VERSION "created by canmatrix"

NS_ :

BS_:

BU_: User ADM_PC_LL25 ADM_PC_BC25 ADM_PC_BP25 ADM_PC_BI25

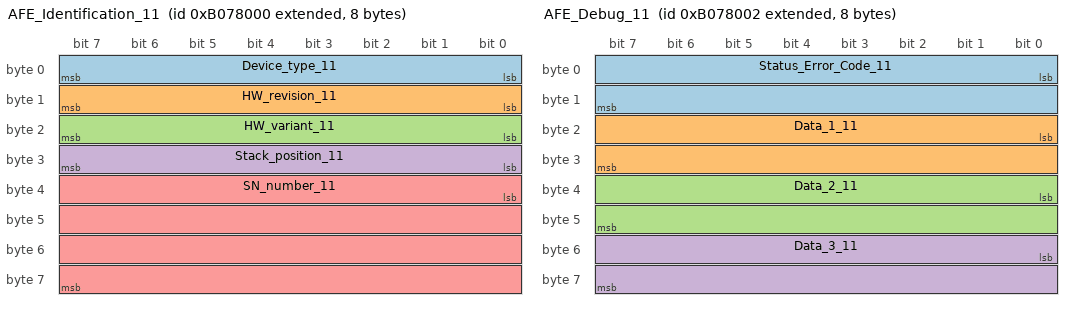
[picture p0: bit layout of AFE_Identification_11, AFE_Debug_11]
BO_ 2332524544 AFE_Identification_11: 8 ADM_PC_BP25
 SG_ Device_type_11 : 0|8@1+ (1,0) [0|255] "" Vector__XXX
 SG_ HW_revision_11 : 8|8@1+ (1,0) [0|255] "" Vector__XXX
 SG_ HW_variant_11 : 16|8@1+ (1,0) [0|255] "" Vector__XXX
 SG_ Stack_position_11 : 24|8@1+ (1,0) [0|255] "" Vector__XXX
 SG_ SN_number_11 : 32|32@1+ (1,0) [0|4294967295] "" Vector__XXX

BO_ 2332524545 AFE_FwInfo_11: 8 ADM_PC_BP25
 SG_ FW_info_mux_11 M : 56|8@1+ (1,0) [0|255] "" Vector__XXX
 SG_ FW_revision_0_11 m0 : 0|8@1+ (1,0) [0|255] "" Vector__XXX
 SG_ FW_revision_1_11 m0 : 8|8@1+ (1,0) [0|255] "" Vector__XXX
 SG_ FW_revision_2_11 m0 : 16|8@1+ (1,0) [0|255] "" Vector__XXX
 SG_ FW_revision_3_11 m0 : 24|8@1+ (1,0) [0|255] "" Vector__XXX
 SG_ FW_revision_4_11 m0 : 32|8@1+ (1,0) [0|255] "" Vector__XXX
 SG_ FW_revision_5_11 m0 : 40|8@1+ (1,0) [0|255] "" Vector__XXX
 SG_ FW_revision_6_11 m0 : 48|8@1+ (1,0) [0|255] "" Vector__XXX
 SG_ FW_revision_7_11 m1 : 0|8@1+ (1,0) [0|255] "" Vector__XXX
 SG_ FW_revision_8_11 m1 : 8|8@1+ (1,0) [0|255] "" Vector__XXX
 SG_ FW_revision_9_11 m1 : 16|8@1+ (1,0) [0|255] "" Vector__XXX
 SG_ FW_revision_10_11 m1 : 24|8@1+ (1,0) [0|255] "" Vector__XXX
 SG_ FW_revision_11_11 m1 : 32|8@1+ (1,0) [0|255] "" Vector__XXX
 SG_ FW_revision_12_11 m1 : 40|8@1+ (1,0) [0|255] "" Vector__XXX
 SG_ FW_revision_13_11 m1 : 48|8@1+ (1,0) [0|255] "" Vector__XXX
 SG_ FW_datecode_0_11 m2 : 0|8@1+ (1,0) [0|255] "" Vector__XXX
 SG_ FW_datecode_1_11 m2 : 8|8@1+ (1,0) [0|255] "" Vector__XXX
 SG_ FW_datecode_2_11 m2 : 16|8@1+ (1,0) [0|255] "" Vector__XXX
 SG_ FW_datecode_3_11 m2 : 24|8@1+ (1,0) [0|255] "" Vector__XXX
 SG_ FW_datecode_4_11 m2 : 32|8@1+ (1,0) [0|255] "" Vector__XXX
 SG_ FW_datecode_5_11 m2 : 40|8@1+ (1,0) [0|255] "" Vector__XXX
 SG_ FW_datecode_6_11 m2 : 48|8@1+ (1,0) [0|255] "" Vector__XXX
 SG_ FW_datecode_7_11 m3 : 0|8@1+ (1,0) [0|255] "" Vector__XXX
 SG_ FW_datecode_8_11 m3 : 8|8@1+ (1,0) [0|255] "" Vector__XXX
 SG_ FW_datecode_9_11 m3 : 16|8@1+ (1,0) [0|255] "" Vector__XXX
 SG_ FW_datecode_10_11 m3 : 24|8@1+ (1,0) [0|255] "" Vector__XXX
 SG_ FW_datecode_11_11 m3 : 32|8@1+ (1,0) [0|255] "" Vector__XXX
 SG_ FW_datecode_12_11 m3 : 40|8@1+ (1,0) [0|255] "" Vector__XXX
 SG_ FW_datecode_13_11 m3 : 48|8@1+ (1,0) [0|255] "" Vector__XXX

BO_ 2332524557 _AFE_Boot_FwInfo_11: 8 ADM_PC_BP25
 SG_ Boot_FW_info_mux_11 M : 56|8@1+ (1,0) [0|255] "" Vector__XXX
 SG_ FW_revision_0_11 m0 : 0|8@1+ (1,0) [0|255] "" Vector__XXX
 SG_ FW_revision_1_11 m0 : 8|8@1+ (1,0) [0|255] "" Vector__XXX
 SG_ FW_revision_2_11 m0 : 16|8@1+ (1,0) [0|255] "" Vector__XXX
 SG_ FW_revision_3_11 m0 : 24|8@1+ (1,0) [0|255] "" Vector__XXX
 SG_ FW_revision_4_11 m0 : 32|8@1+ (1,0) [0|255] "" Vector__XXX
 SG_ FW_revision_5_11 m0 : 40|8@1+ (1,0) [0|255] "" Vector__XXX
 SG_ FW_revision_6_11 m0 : 48|8@1+ (1,0) [0|255] "" Vector__XXX
 SG_ FW_revision_7_11 m1 : 0|8@1+ (1,0) [0|255] "" Vector__XXX
 SG_ FW_revision_8_11 m1 : 8|8@1+ (1,0) [0|255] "" Vector__XXX
 SG_ FW_revision_9_11 m1 : 16|8@1+ (1,0) [0|255] "" Vector__XXX
 SG_ FW_revision_10_11 m1 : 24|8@1+ (1,0) [0|255] "" Vector__XXX
 SG_ FW_revision_11_11 m1 : 32|8@1+ (1,0) [0|255] "" Vector__XXX
 SG_ FW_revision_12_11 m1 : 40|8@1+ (1,0) [0|255] "" Vector__XXX
 SG_ FW_revision_13_11 m1 : 48|8@1+ (1,0) [0|255] "" Vector__XXX
 SG_ FW_datecode_0_11 m2 : 0|8@1+ (1,0) [0|255] "" Vector__XXX
 SG_ FW_datecode_1_11 m2 : 8|8@1+ (1,0) [0|255] "" Vector__XXX
 SG_ FW_datecode_2_11 m2 : 16|8@1+ (1,0) [0|255] "" Vector__XXX
 SG_ FW_datecode_3_11 m2 : 24|8@1+ (1,0) [0|255] "" Vector__XXX
 SG_ FW_datecode_4_11 m2 : 32|8@1+ (1,0) [0|255] "" Vector__XXX
 SG_ FW_datecode_5_11 m2 : 40|8@1+ (1,0) [0|255] "" Vector__XXX
 SG_ FW_datecode_6_11 m2 : 48|8@1+ (1,0) [0|255] "" Vector__XXX
 SG_ FW_datecode_7_11 m3 : 0|8@1+ (1,0) [0|255] "" Vector__XXX
 SG_ FW_datecode_8_11 m3 : 8|8@1+ (1,0) [0|255] "" Vector__XXX
 SG_ FW_datecode_9_11 m3 : 16|8@1+ (1,0) [0|255] "" Vector__XXX
 SG_ FW_datecode_10_11 m3 : 24|8@1+ (1,0) [0|255] "" Vector__XXX
 SG_ FW_datecode_11_11 m3 : 32|8@1+ (1,0) [0|255] "" Vector__XXX
 SG_ FW_datecode_12_11 m3 : 40|8@1+ (1,0) [0|255] "" Vector__XXX
 SG_ FW_datecode_13_11 m3 : 48|8@1+ (1,0) [0|255] "" Vector__XXX

BO_ 2332524546 AFE_Debug_11: 8 ADM_PC_BP25
 SG_ Status_Error_Code_11 : 0|16@1+ (1,0) [0|65535] "" Vector__XXX
 SG_ Data_1_11 : 16|16@1+ (1,0) [0|65535] "" Vector__XXX
 SG_ Data_2_11 : 32|16@1+ (1,0) [0|65535] "" Vector__XXX
 SG_ Data_3_11 : 48|16@1+ (1,0) [0|65535] "" Vector__XXX

BO_ 2332524551 AFE_Status_11: 8 ADM_PC_BP25
 SG_ Running_11 : 0|1@1+ (1,0) [0|1] "" Vector__XXX
 SG_ PWM_11 : 1|1@1+ (1,0) [0|1] "" Vector__XXX
 SG_ Current_dc_loop_mode_11 : 2|1@1+ (1,0) [0|1] "" Vector__XXX
 SG_ Current_ac_loop_mode_11 : 3|1@1+ (1,0) [0|1] "" Vector__XXX
 SG_ Buck_11 : 5|1@1+ (1,0) [0|1] "" Vector__XXX
 SG_ Boost_11 : 6|1@1+ (1,0) [0|1] "" Vector__XXX
 SG_ Precharge_dc_buck_mode_11 : 7|1@1+ (1,0) [0|1] "" Vector__XXX
 SG_ Precharge_dc_boost_mode_11 : 8|1@1+ (1,0) [0|1] "" Vector__XXX
 SG_ Rectifier_3ph_11 : 9|1@1+ (1,0) [0|1] "" Vector__XXX
 SG_ Stack_mode_11 : 10|1@1+ (1,0) [0|1] "" Vector__XXX
 SG_ Master_11 : 11|1@1+ (1,0) [0|1] "" Vector__XXX
 SG_ Slave_11 : 12|1@1+ (1,0) [0|1] "" Vector__XXX
 SG_ Inverter_1ph_11 : 13|1@1+ (1,0) [0|1] "" Vector__XXX
 SG_ Boost_Neutral_11 : 14|1@1+ (1,0) [0|1] "" Vector__XXX
 SG_ Rectifier_1ph_11 : 15|1@1+ (1,0) [0|1] "" Vector__XXX
 SG_ Inverter_3ph_11 : 16|1@1+ (1,0) [0|1] "" Vector__XXX
 SG_ Ready_11 : 17|1@1+ (1,0) [0|1] "" Vector__XXX
 SG_ Inverter_1ph_Sync_11 : 18|1@1+ (1,0) [0|1] "" Vector__XXX
 SG_ Neutral_11 : 19|1@1+ (1,0) [0|1] "" Vector__XXX
 SG_ Rectifier_1ph_Buck_11 : 20|1@1+ (1,0) [0|1] "" Vector__XXX
 SG_ Inverter_1ph_Boost_11 : 21|1@1+ (1,0) [0|1] "" Vector__XXX
 SG_ Rectifier_distributed_11 : 22|1@1+ (1,0) [0|1] "" Vector__XXX
 SG_ MPPT_buck_11 : 23|1@1+ (1,0) [0|1] "" Vector__XXX
 SG_ MPPT_boost_11 : 24|1@1+ (1,0) [0|1] "" Vector__XXX
 SG_ Buck_2p_float_11 : 25|1@1+ (1,0) [0|1] "" Vector__XXX
 SG_ Inverter_1ph_Distributed_11 : 26|1@1+ (1,0) [0|1] "" Vector__XXX

BO_ 2332524550 AFE_Faults_11: 3 ADM_PC_BP25
 SG_ Protection_trip_internal_11 : 0|1@1+ (1,0) [0|1] "" Vector__XXX
 SG_ Protection_trip_external_11 : 1|1@1+ (1,0) [0|1] "" Vector__XXX
 SG_ Phase_U_overcurrent_11 : 2|1@1+ (1,0) [0|1] "" Vector__XXX
 SG_ Phase_U_overvoltage_11 : 3|1@1+ (1,0) [0|1] "" Vector__XXX
 SG_ Phase_U_undervoltage_11 : 4|1@1+ (1,0) [0|1] "" Vector__XXX
 SG_ Phase_V_overvoltage_11 : 5|1@1+ (1,0) [0|1] "" Vector__XXX
 SG_ Phase_V_undervoltage_11 : 6|1@1+ (1,0) [0|1] "" Vector__XXX
 SG_ Phase_V_overcurrent_11 : 7|1@1+ (1,0) [0|1] "" Vector__XXX
 SG_ Phase_W_overvoltage_11 : 8|1@1+ (1,0) [0|1] "" Vector__XXX
 SG_ Phase_W_undervoltage_11 : 9|1@1+ (1,0) [0|1] "" Vector__XXX
 SG_ Phase_W_overcurrent_11 : 10|1@1+ (1,0) [0|1] "" Vector__XXX
 SG_ DC_undervoltage_11 : 11|1@1+ (1,0) [0|1] "" Vector__XXX
 SG_ DC_overvoltage_11 : 12|1@1+ (1,0) [0|1] "" Vector__XXX
 SG_ MOSFET_overtemperature_11 : 13|1@1+ (1,0) [0|1] "" Vector__XXX
 SG_ Inductor_overtemperature_11 : 14|1@1+ (1,0) [0|1] "" Vector__XXX
 SG_ Keep_Alive_not_served_11 : 15|1@1+ (1,0) [0|1] "" Vector__XXX
 SG_ PLL_not_locked_11 : 16|1@1+ (1,0) [0|1] "" Vector__XXX
 SG_ NFO_11 : 20|1@1+ (1,0) [0|1] "" Vector__XXX
 SG_ Measurement_system_failure_11 : 21|1@1+ (1,0) [0|1] "" Vector__XXX
 SG_ EEPROM_failure_11 : 22|1@1+ (1,0) [0|1] "" Vector__XXX
 SG_ System_11 : 23|1@1+ (1,0) [0|1] "" Vector__XXX

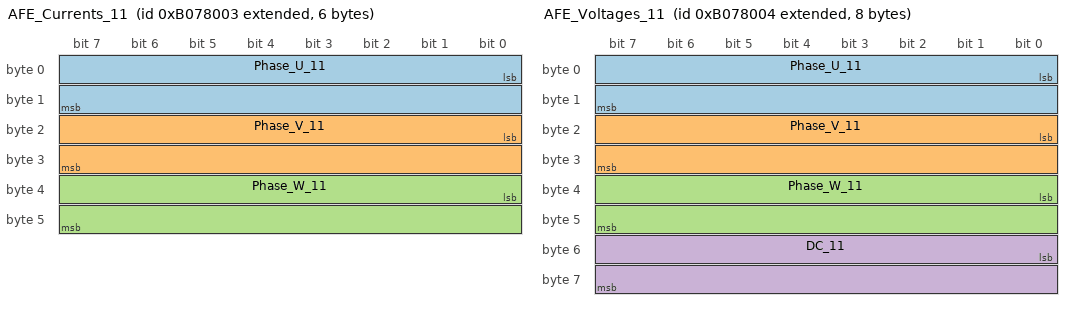
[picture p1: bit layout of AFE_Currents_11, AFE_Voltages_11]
BO_ 2332524547 AFE_Currents_11: 6 ADM_PC_BP25
 SG_ Phase_U_11 : 0|16@1- (0.01,0) [-327.68|327.67] "A" Vector__XXX
 SG_ Phase_V_11 : 16|16@1- (0.01,0) [-327.68|327.67] "A" Vector__XXX
 SG_ Phase_W_11 : 32|16@1- (0.01,0) [-327.68|327.67] "A" Vector__XXX

BO_ 2332524560 AFE_DC_Bus_current_11: 2 ADM_PC_BP25
 SG_ Bus_current_11 : 0|16@1- (0.01,0) [-327.68|327.67] "A" Vector__XXX

BO_ 2332524558 _AFE_Broadcast_11: 8 ADM_PC_BP25
 SG_ Diagnostics_Index_11 M : 56|8@1+ (1,0) [0|255] "" Vector__XXX
 SG_ Phase_U_11 m1 : 8|16@1- (0.01,0) [-327.68|327.67] "A" ADM_PC_BP25
 SG_ Phase_V_11 m1 : 24|16@1- (0.01,0) [-327.68|327.67] "A" ADM_PC_BP25
 SG_ Phase_W_11 m1 : 40|16@1- (0.01,0) [-327.68|327.67] "A" ADM_PC_BP25
 SG_ Stack_position_11 : 0|5@1+ (1,0) [0|31] "" ADM_PC_BP25
 SG_ Group_ID_11 : 5|3@1+ (1,0) [0|7] "" ADM_PC_BP25

BO_ 2332524548 AFE_Voltages_11: 8 ADM_PC_BP25
 SG_ Phase_U_11 : 0|16@1- (0.1,0) [-3276.8|3276.7] "V" Vector__XXX
 SG_ Phase_V_11 : 16|16@1- (0.1,0) [-3276.8|3276.7] "V" Vector__XXX
 SG_ Phase_W_11 : 32|16@1- (0.1,0) [-3276.8|3276.7] "V" Vector__XXX
 SG_ DC_11 : 48|16@1- (0.1,0) [-3276.8|3276.7] "V" Vector__XXX

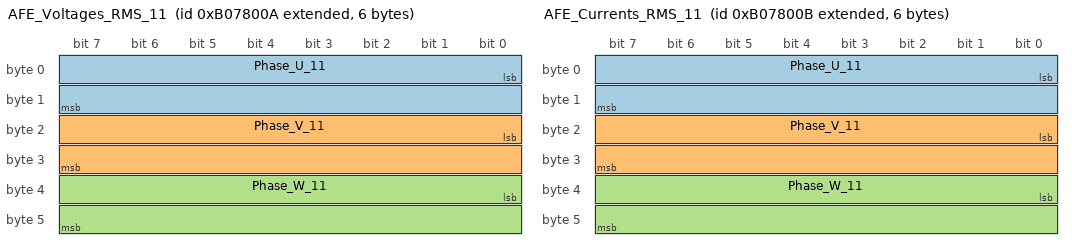
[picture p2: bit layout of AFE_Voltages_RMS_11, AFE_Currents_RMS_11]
BO_ 2332524554 AFE_Voltages_RMS_11: 6 ADM_PC_BP25
 SG_ Phase_U_11 : 0|16@1+ (0.1,0) [0|6553.5] "V" Vector__XXX
 SG_ Phase_V_11 : 16|16@1+ (0.1,0) [0|6553.5] "V" Vector__XXX
 SG_ Phase_W_11 : 32|16@1+ (0.1,0) [0|6553.5] "V" Vector__XXX

BO_ 2332524555 AFE_Currents_RMS_11: 6 ADM_PC_BP25
 SG_ Phase_U_11 : 0|16@1+ (0.01,0) [0.00|655.35] "A" Vector__XXX
 SG_ Phase_V_11 : 16|16@1+ (0.01,0) [0.00|655.35] "A" Vector__XXX
 SG_ Phase_W_11 : 32|16@1+ (0.01,0) [0.00|655.35] "A" Vector__XXX

BO_ 2332524556 AFE_Mains_11: 4 ADM_PC_BP25
 SG_ Frequency_11 : 0|16@1+ (0.01,0) [0.00|655.35] "Hz" Vector__XXX
 SG_ Phase_11 : 16|16@1- (0.1,0) [-3276.8|3276.7] "Deg." Vector__XXX

BO_ 2332524549 AFE_Temperatures_11: 4 ADM_PC_BP25
 SG_ Temp_Bridge_11 : 0|16@1- (0.01,0) [-327.68|327.67] "°C" Vector__XXX
 SG_ Temp_Inductors_11 : 16|16@1- (0.01,0) [-327.68|327.67] "°C" Vector__XXX

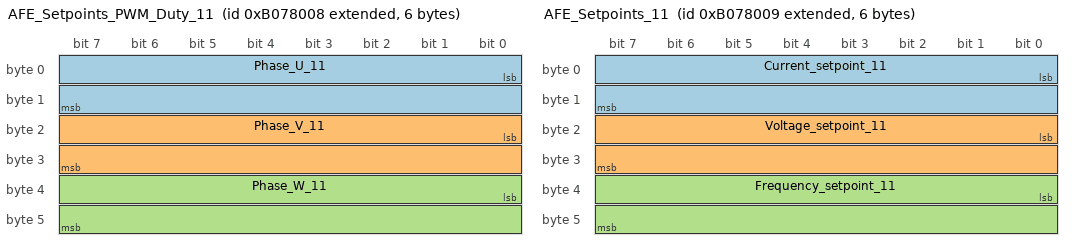
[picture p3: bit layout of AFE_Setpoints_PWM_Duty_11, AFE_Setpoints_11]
BO_ 2332524552 AFE_Setpoints_PWM_Duty_11: 6 ADM_PC_BP25
 SG_ Phase_U_11 : 0|16@1+ (0.001525902,0) [0E-009|99.999987570] "%" Vector__XXX
 SG_ Phase_V_11 : 16|16@1+ (0.001525902,0) [0E-009|99.999987570] "%" Vector__XXX
 SG_ Phase_W_11 : 32|16@1+ (0.001525902,0) [0E-009|99.999987570] "%" Vector__XXX

BO_ 2332524553 AFE_Setpoints_11: 6 ADM_PC_BP25
 SG_ Current_setpoint_11 : 0|16@1- (0.01,0) [-327.68|327.67] "A" Vector__XXX
 SG_ Voltage_setpoint_11 : 16|16@1+ (0.1,0) [0|6553.5] "V" Vector__XXX
 SG_ Frequency_setpoint_11 : 32|16@1+ (0.01,0) [0.00|655.35] "Hz" Vector__XXX

BO_ 2332491872 AFE_Keep_Alive_11: 1 User
 SG_ Keep_Alive_Enable_11 : 0|1@1+ (1,0) [0|1] "" ADM_PC_BP25

BO_ 2332491840 AFE_Mode_Control_11: 8 User
 SG_ Converter_ON_11 : 0|1@1+ (1,0) [0|1] "" ADM_PC_BP25
 SG_ PWM_ON_11 : 1|1@1+ (1,0) [0|1] "" ADM_PC_BP25
 SG_ DC_Current_feedback_ON_11 : 2|1@1+ (1,0) [0|1] "" ADM_PC_BP25
 SG_ AC_Current_feedback_ON_11 : 3|1@1+ (1,0) [0|1] "" ADM_PC_BP25
 SG_ Buck_ON_11 : 5|1@1+ (1,0) [0|1] "" ADM_PC_BP25
 SG_ Boost_ON_11 : 6|1@1+ (1,0) [0|1] "" ADM_PC_BP25
 SG_ Rectifier_3ph_ON_11 : 9|1@1+ (1,0) [0|1] "" ADM_PC_BP25
 SG_ Inverter_1ph_ON_11 : 10|1@1+ (1,0) [0|1] "" ADM_PC_BP25
 SG_ Rectifier_1ph_ON_11 : 11|1@1+ (1,0) [0|1] "" ADM_PC_BP25
 SG_ Boost_Neutral_ON_11 : 12|1@1+ (1,0) [0|1] "" ADM_PC_BP25
 SG_ Inverter_3ph_ON_11 : 13|1@1+ (1,0) [0|1] "" ADM_PC_BP25
 SG_ Inverter_1ph_Sync_ON_11 : 14|1@1+ (1,0) [0|1] "" ADM_PC_BP25
 SG_ Neutral_ON_11 : 15|1@1+ (1,0) [0|1] "" ADM_PC_BP25
 SG_ Rectifier_1ph_Buck_ON_11 : 16|1@1+ (1,0) [0|1] "" ADM_PC_BP25
 SG_ Inverter_1ph_Boost_ON_11 : 17|1@1+ (1,0) [0|1] "" ADM_PC_BP25
 SG_ Rectifier_Distributed_ON_11 : 18|1@1+ (1,0) [0|1] "" ADM_PC_BP25
 SG_ MPPT_buck_ON_11 : 19|1@1+ (1,0) [0|1] "" ADM_PC_BP25
 SG_ MPPT_boost_ON_11 : 20|1@1+ (1,0) [0|1] "" ADM_PC_BP25
 SG_ Buck_2p_float_ON_11 : 21|1@1+ (1,0) [0|1] "" ADM_PC_BP25
 SG_ Inverter_1ph_Distributed_ON_11 : 22|1@1+ (1,0) [0|1] "" ADM_PC_BP25

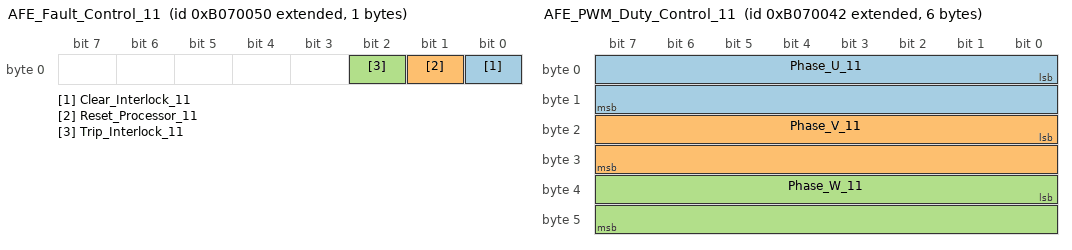
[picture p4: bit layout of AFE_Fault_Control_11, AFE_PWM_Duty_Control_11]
BO_ 2332491856 AFE_Fault_Control_11: 1 User
 SG_ Clear_Interlock_11 : 0|1@1+ (1,0) [0|1] "" ADM_PC_BP25
 SG_ Reset_Processor_11 : 1|1@1+ (1,0) [0|1] "" ADM_PC_BP25
 SG_ Trip_Interlock_11 : 2|1@1+ (1,0) [0|1] "" ADM_PC_BP25

BO_ 2332491841 AFE_Reactive_Current_Setpoint_Co: 2 User
 SG_ Reactive_current_setpoint_11 : 0|16@1- (0.01,0) [-150|150] "A" ADM_PC_BP25

BO_ 2332491842 AFE_PWM_Duty_Control_11: 6 User
 SG_ Phase_U_11 : 0|16@1+ (0.001525902,0) [0E-009|99.999987570] "%" ADM_PC_BP25
 SG_ Phase_V_11 : 16|16@1+ (0.001525902,0) [0E-009|99.999987570] "%" ADM_PC_BP25
 SG_ Phase_W_11 : 32|16@1+ (0.001525902,0) [0E-009|99.999987570] "%" ADM_PC_BP25

BO_ 2332491843 AFE_Current_Setpoint_Control_11: 2 User
 SG_ Current_setpoint_11 : 0|16@1- (0.01,0) [-150|150] "A" ADM_PC_BP25

BO_ 2332491844 AFE_Voltage_Setpoint_Control_11: 2 User
 SG_ Voltage_setpoint_11 : 0|16@1+ (0.1,0) [0|1500] "V" ADM_PC_BP25

BO_ 2332491848 AFE_Frequency_Setpoint_Control_1: 2 User
 SG_ Frequency_setpoint_11 : 0|16@1+ (0.01,0) [40|70] "Hz" ADM_PC_BP25

BO_ 2332491849 AFE_Phase_Setpoint_Control_11: 2 User
 SG_ Phase_setpoint_11 : 0|16@1+ (1,0) [0|360] "deg" ADM_PC_BP25

BO_ 2332491888 AFE_Rectifier_Setpoint_Control_1: 8 User
 SG_ Voltage_setpoint_2_11 : 0|16@1+ (0.1,0) [0|1500] "V" ADM_PC_BP25
 SG_ Current_setpoint_2_11 : 16|16@1- (0.01,0) [-150|150] "A" ADM_PC_BP25

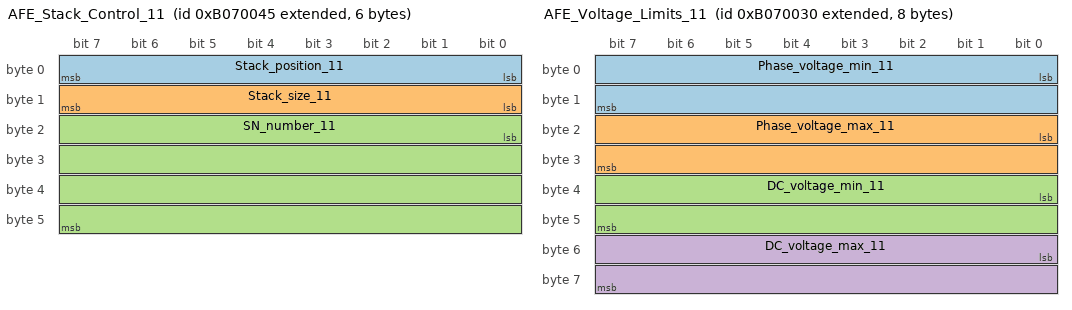
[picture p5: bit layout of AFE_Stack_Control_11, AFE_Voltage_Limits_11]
BO_ 2332491845 AFE_Stack_Control_11: 6 User
 SG_ Stack_position_11 : 0|8@1+ (1,0) [0|255] "" ADM_PC_BP25
 SG_ Stack_size_11 : 8|8@1+ (1,0) [0|255] "" ADM_PC_BP25
 SG_ SN_number_11 : 16|32@1+ (1,0) [0|4294967295] "" ADM_PC_BP25

BO_ 2332491824 AFE_Voltage_Limits_11: 8 User
 SG_ Phase_voltage_min_11 : 0|16@1- (0.1,0) [0|3276.7] "V" ADM_PC_BP25
 SG_ Phase_voltage_max_11 : 16|16@1- (0.1,0) [-3276.8|850] "V" ADM_PC_BP25
 SG_ DC_voltage_min_11 : 32|16@1- (0.1,0) [0|3276.7] "V" ADM_PC_BP25
 SG_ DC_voltage_max_11 : 48|16@1- (0.1,0) [-3276.8|850] "V" ADM_PC_BP25

BO_ 2332491825 AFE_Current_Limits_11: 4 User
 SG_ Phase_current_min_11 : 0|16@1- (0.01,0) [-60|60] "A" ADM_PC_BP25
 SG_ Phase_current_max_11 : 16|16@1- (0.01,0) [-60|60] "A" ADM_PC_BP25

BO_ 2332491852 AFE_Group_Control_11: 1 User
 SG_ Group_ID_11 : 0|8@1+ (1,0) [0|255] "" ADM_PC_BP25

BO_ 2332524559 AFE_Group_Info_11: 1 ADM_PC_BP25
 SG_ Group_ID_11 : 0|8@1+ (1,0) [0|255] "" Vector__XXX

BO_ 2332491873 AFE_System_Flags_Control_11: 8 User
 SG_ Factory_mode_11 : 0|1@1+ (1,0) [0|1] "" ADM_PC_BP25
 SG_ Silent_CAN_mode_11 : 1|1@1+ (1,0) [0|1] "" ADM_PC_BP25

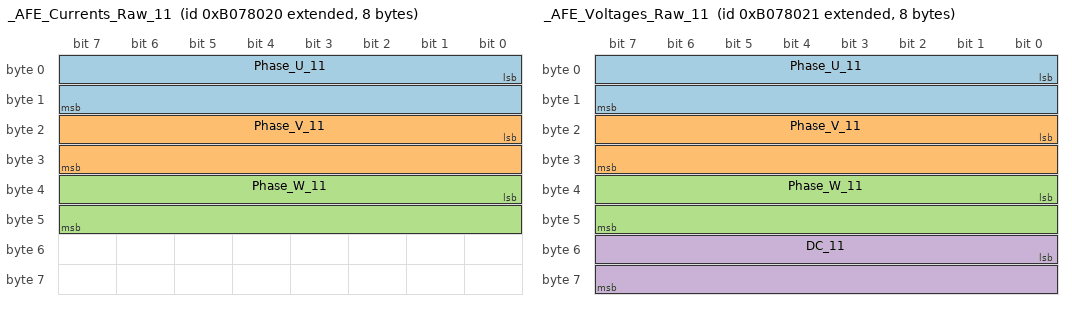
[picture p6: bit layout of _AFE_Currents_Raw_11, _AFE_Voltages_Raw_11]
BO_ 2332524576 _AFE_Currents_Raw_11: 8 ADM_PC_BP25
 SG_ Phase_U_11 : 0|16@1- (1,0) [-32768|32767] "" Vector__XXX
 SG_ Phase_V_11 : 16|16@1- (1,0) [-32768|32767] "" Vector__XXX
 SG_ Phase_W_11 : 32|16@1- (1,0) [-32768|32767] "" Vector__XXX

BO_ 2332524577 _AFE_Voltages_Raw_11: 8 ADM_PC_BP25
 SG_ Phase_U_11 : 0|16@1- (1,0) [-32768|32767] "" Vector__XXX
 SG_ Phase_V_11 : 16|16@1- (1,0) [-32768|32767] "" Vector__XXX
 SG_ Phase_W_11 : 32|16@1- (1,0) [-32768|32767] "" Vector__XXX
 SG_ DC_11 : 48|16@1- (1,0) [-32768|32767] "" Vector__XXX

BO_ 2332491850 _AFE_ADC_Calibration_Mode_11: 1 User
 SG_ Calibration_Index_11 M : 2|5@1+ (1,0) [0|31] "" Vector__XXX
 SG_ Current_U_11 m1 : 0|2@1+ (1,0) [0|3] "" ADM_PC_BP25
 SG_ Current_V_11 m2 : 0|2@1+ (1,0) [0|3] "" ADM_PC_BP25
 SG_ Current_W_11 m3 : 0|2@1+ (1,0) [0|3] "" ADM_PC_BP25
 SG_ Voltage_U_11 m4 : 0|2@1+ (1,0) [0|3] "" ADM_PC_BP25
 SG_ Voltage_V_11 m5 : 0|2@1+ (1,0) [0|3] "" ADM_PC_BP25
 SG_ Voltage_W_11 m6 : 0|2@1+ (1,0) [0|3] "" ADM_PC_BP25
 SG_ Voltage_DC_11 m7 : 0|2@1+ (1,0) [0|3] "" ADM_PC_BP25
 SG_ start_11 : 7|1@1+ (1,0) [0|1] "" ADM_PC_BP25

BO_ 2332491851 _AFE_ADC_Calibration_Setpoint_11: 3 User
 SG_ Calibration_Index_11 M : 16|5@1+ (1,0) [0|31] "" Vector__XXX
 SG_ Current_U_11 m1 : 0|16@1- (0.01,0) [-100|100] "A" ADM_PC_BP25
 SG_ Current_V_11 m2 : 0|16@1- (0.01,0) [-100|100] "A" ADM_PC_BP25
 SG_ Current_W_11 m3 : 0|16@1- (0.01,0) [-100|100] "A" ADM_PC_BP25
 SG_ Voltage_U_11 m4 : 0|16@1+ (0.1,0) [0|1500] "V" ADM_PC_BP25
 SG_ Voltage_V_11 m5 : 0|16@1+ (0.1,0) [0|1500] "V" ADM_PC_BP25
 SG_ Voltage_W_11 m6 : 0|16@1+ (0.1,0) [0|1500] "V" ADM_PC_BP25
 SG_ Voltage_DC_11 m7 : 0|16@1+ (0.1,0) [0|1500] "V" ADM_PC_BP25
 SG_ point_11 : 21|3@1+ (1,0) [0|7] "" ADM_PC_BP25

BO_ 2332491846 _AFE_Calibration_Offset_Update_1: 6 User
 SG_ Calibration_Index_11 M : 16|16@1+ (1,0) [0|65535] "" Vector__XXX
 SG_ Current_U_11 m0 : 0|16@1- (1,0) [-32768|32767] "ADC Counts" ADM_PC_BP25
 SG_ Current_V_11 m1 : 0|16@1- (1,0) [-32768|32767] "ADC Counts" ADM_PC_BP25
 SG_ Current_W_11 m2 : 0|16@1- (1,0) [-32768|32767] "ADC Counts" ADM_PC_BP25
 SG_ Voltage_U_11 m3 : 0|16@1- (1,0) [-32768|32767] "ADC Counts" ADM_PC_BP25
 SG_ Voltage_V_11 m4 : 0|16@1- (1,0) [-32768|32767] "ADC Counts" ADM_PC_BP25
 SG_ Voltage_W_11 m5 : 0|16@1- (1,0) [-32768|32767] "ADC Counts" ADM_PC_BP25
 SG_ Voltage_DC_11 m6 : 0|16@1- (1,0) [-32768|32767] "ADC Counts" ADM_PC_BP25
 SG_ CRC_11 : 32|16@1+ (1,0) [0|65535] "-" ADM_PC_BP25

BO_ 2332491847 _AFE_Calibration_Scale_Update_11: 6 User
 SG_ Calibration_Index_11 M : 16|16@1+ (1,0) [0|65535] "" Vector__XXX
 SG_ Current_U_11 m0 : 0|16@1- (0.0000152587890625,0) [-0.5000000000000000|0.4999847412109375] "scale = 1.0 + value" ADM_PC_BP25
 SG_ Current_V_11 m1 : 0|16@1- (0.0000152587890625,0) [-0.5000000000000000|0.4999847412109375] "scale = 1.0 + value" ADM_PC_BP25
 SG_ Current_W_11 m2 : 0|16@1- (0.0000152587890625,0) [-0.5000000000000000|0.4999847412109375] "scale = 1.0 + value" ADM_PC_BP25
 SG_ Voltage_U_11 m3 : 0|16@1- (0.0000152587890625,0) [-0.5000000000000000|0.4999847412109375] "scale = 1.0 + value" ADM_PC_BP25
 SG_ Voltage_V_11 m4 : 0|16@1- (0.0000152587890625,0) [-0.5000000000000000|0.4999847412109375] "scale = 1.0 + value" ADM_PC_BP25
 SG_ Voltage_W_11 m5 : 0|16@1- (0.0000152587890625,0) [-0.5000000000000000|0.4999847412109375] "scale = 1.0 + value" ADM_PC_BP25
 SG_ Voltage_DC_11 m6 : 0|16@1- (0.0000152587890625,0) [-0.5000000000000000|0.4999847412109375] "scale = 1.0 + value" ADM_PC_BP25
 SG_ CRC_11 : 32|16@1+ (1,0) [0|65535] "-" ADM_PC_BP25

BO_ 2332524625 _AFE_Calibration_Adc_Scale_11: 6 ADM_PC_BP25
 SG_ Adc_Index_11 M : 32|16@1+ (1,0) [0|65535] "" Vector__XXX
 SG_ Current_U_11 m0 : 0|32@1+ (1,0) [0|4294967295] "1 / adc_bins" User
 SG_ Current_V_11 m1 : 0|32@1+ (1,0) [0|4294967295] "1 / adc_bins" User
 SG_ Current_W_11 m2 : 0|32@1+ (1,0) [0|4294967295] "1 / adc_bins" User
 SG_ Voltage_U_11 m3 : 0|32@1+ (1,0) [0|4294967295] "1 / adc_bins" User
 SG_ Voltage_V_11 m4 : 0|32@1+ (1,0) [0|4294967295] "1 / adc_bins" User
 SG_ Voltage_W_11 m5 : 0|32@1+ (1,0) [0|4294967295] "1 / adc_bins" User
 SG_ Voltage_DC_11 m6 : 0|32@1+ (1,0) [0|4294967295] "1 / adc_bins" User

BO_ 2332524626 _AFE_Calibration_Adc_Fs_11: 6 ADM_PC_BP25
 SG_ Adc_Index_11 M : 32|16@1+ (1,0) [0|65535] "" Vector__XXX
 SG_ Current_U_11 m0 : 0|32@1+ (1,0) [0|4294967295] "Fullscale" User
 SG_ Current_V_11 m1 : 0|32@1+ (1,0) [0|4294967295] "Fullscale" User
 SG_ Current_W_11 m2 : 0|32@1+ (1,0) [0|4294967295] "Fullscale" User
 SG_ Voltage_U_11 m3 : 0|32@1+ (1,0) [0|4294967295] "Fullscale" User
 SG_ Voltage_V_11 m4 : 0|32@1+ (1,0) [0|4294967295] "Fullscale" User
 SG_ Voltage_W_11 m5 : 0|32@1+ (1,0) [0|4294967295] "Fullscale" User
 SG_ Voltage_DC_11 m6 : 0|32@1+ (1,0) [0|4294967295] "Fullscale" User

BO_ 2332524627 _AFE_Calibration_Adc_Offset_11: 4 ADM_PC_BP25
 SG_ Adc_Index_11 M : 16|16@1+ (1,0) [0|65535] "" Vector__XXX
 SG_ Current_U_11 m0 : 0|16@1- (1,0) [-32768|32767] "-" User
 SG_ Current_V_11 m1 : 0|16@1- (1,0) [-32768|32767] "-" User
 SG_ Current_W_11 m2 : 0|16@1- (1,0) [-32768|32767] "-" User
 SG_ Voltage_U_11 m3 : 0|16@1- (1,0) [-32768|32767] "-" User
 SG_ Voltage_V_11 m4 : 0|16@1- (1,0) [-32768|32767] "-" User
 SG_ Voltage_W_11 m5 : 0|16@1- (1,0) [-32768|32767] "-" User
 SG_ Voltage_DC_11 m6 : 0|16@1- (1,0) [-32768|32767] "-" User

BO_ 2332524628 _AFE_Calibration_Adc_Gain_11: 4 ADM_PC_BP25
 SG_ Adc_Index_11 M : 16|16@1+ (1,0) [0|65535] "" Vector__XXX
 SG_ Current_U_11 m0 : 0|16@1- (1,0) [-32768|32767] "-" User
 SG_ Current_V_11 m1 : 0|16@1- (1,0) [-32768|32767] "-" User
 SG_ Current_W_11 m2 : 0|16@1- (1,0) [-32768|32767] "-" User
 SG_ Voltage_U_11 m3 : 0|16@1- (1,0) [-32768|32767] "-" User
 SG_ Voltage_V_11 m4 : 0|16@1- (1,0) [-32768|32767] "-" User
 SG_ Voltage_W_11 m5 : 0|16@1- (1,0) [-32768|32767] "-" User
 SG_ Voltage_DC_11 m6 : 0|16@1- (1,0) [-32768|32767] "-" User

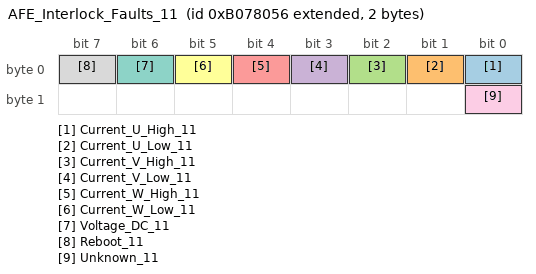
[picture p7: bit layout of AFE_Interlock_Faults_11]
BO_ 2332524630 AFE_Interlock_Faults_11: 2 ADM_PC_BP25
 SG_ Current_U_High_11 : 0|1@1+ (1,0) [0|1] "" Vector__XXX
 SG_ Current_U_Low_11 : 1|1@1+ (1,0) [0|1] "" Vector__XXX
 SG_ Current_V_High_11 : 2|1@1+ (1,0) [0|1] "" Vector__XXX
 SG_ Current_V_Low_11 : 3|1@1+ (1,0) [0|1] "" Vector__XXX
 SG_ Current_W_High_11 : 4|1@1+ (1,0) [0|1] "" Vector__XXX
 SG_ Current_W_Low_11 : 5|1@1+ (1,0) [0|1] "" Vector__XXX
 SG_ Voltage_DC_11 : 6|1@1+ (1,0) [0|1] "" Vector__XXX
 SG_ Reboot_11 : 7|1@1+ (1,0) [0|1] "" Vector__XXX
 SG_ Unknown_11 : 8|1@1+ (1,0) [0|1] "" Vector__XXX

BO_TX_BU_ 2332491840 : User,ADM_PC_LL25,ADM_PC_BC25,ADM_PC_BI25;
BO_TX_BU_ 2332491843 : User,ADM_PC_LL25,ADM_PC_BC25,ADM_PC_BI25;
BO_TX_BU_ 2332491844 : User,ADM_PC_LL25,ADM_PC_BC25,ADM_PC_BI25;
CM_ BO_ 2332524544  "Identification of the device";
CM_ BO_ 2332524545  "Git revision of the DSP firmware";
CM_ BO_ 2332524557  "Git revision of the bootloader firmware.";
CM_ BO_ 2332524546  "Values for debugging of HW/SW problems";
CM_ BO_ 2332524551  "Status bitfield";
CM_ BO_ 2332524550  "Fault bitfield";
CM_ BO_ 2332524547  "Current of phases U, V, W";
CM_ BO_ 2332524560  "Current of of the DC Bus";
CM_ BO_ 2332524558  "All AFEs will listen to this message";
CM_ BO_ 2332524555  "RMS Current of phases U, V, W";
CM_ BO_ 2332524556  "Three-Phase mains health (frequency, phase...)";
CM_ BO_ 2332524549  "Readouts of the module temperature sensors";
CM_ BO_ 2332524552  "Setpoints";
CM_ BO_ 2332524553  "Setpoints";
CM_ BO_ 2332491872  "Keep alive ping message. ";
CM_ BO_ 2332491840  "Operation Mode control: sets the converter operation mode";
CM_ BO_ 2332491856  "Fault Control: actions to clear faults and reset the system";
CM_ BO_ 2332491841  "Reactive power setpoint control.";
CM_ BO_ 2332491842  "PWM duty cycle control";
CM_ BO_ 2332491843  "Current setpoint control";
CM_ BO_ 2332491844  "Voltage setpoint control";
CM_ BO_ 2332491848  "Frequency setpoint control";
CM_ BO_ 2332491849  "Phase setpoint control";
CM_ BO_ 2332491888  "Additional voltage and current setpoints in single-phase rectifier and inverter control modes.";
CM_ BO_ 2332491845  "PFC stack control";
CM_ BO_ 2332491824  "Set the input and output voltage limits (minimum and maximum)";
CM_ BO_ 2332491825  "Set the output current limits (mminimum and maximum)";
CM_ BO_ 2332491852  "Set the Group ID of the device";
CM_ BO_ 2332524559  "Contains the Group ID of the device";
CM_ BO_ 2332491873  "Control the system flags";
CM_ BO_ 2332524576  "Current of phases A and B";
CM_ BO_ 2332524577  "Current of phases A and B";
CM_ BO_ 2332491850  "Automatic ADC calibration.";
CM_ BO_ 2332491851  "Setpoint for automatic ADC calibration.";
CM_ BO_ 2332491846  "Update of the calibration table for offsets.";
CM_ BO_ 2332491847  "Update of the calibration table for scales.";
CM_ BO_ 2332524625  "
                Adc scale (resolution) value of readouts.
            ";
CM_ BO_ 2332524626  "
                Adc fullscale value of readouts.
            ";
CM_ BO_ 2332524627  "
                Readout of ADC calibration data (offset) from EEPROM.
            ";
CM_ BO_ 2332524628  "
                Readout of ADC calibration data (gain) from EEPROM.
            ";
CM_ BO_ 2332524630  "Fault bitfield";

CM_ SG_ 2332524544 Device_type_11 "The device identification field, uniquely identifies the sender in the network";
CM_ SG_ 2332524544 HW_revision_11 "The hardware revision number";
CM_ SG_ 2332524544 HW_variant_11 "The DSP firmware revision number";
CM_ SG_ 2332524544 Stack_position_11 "Position of the module within the stack";
CM_ SG_ 2332524544 SN_number_11 "Unique module serial number";
CM_ SG_ 2332524545 FW_revision_0_11 "Character 0";
CM_ SG_ 2332524545 FW_revision_1_11 "Character 1";
CM_ SG_ 2332524545 FW_revision_2_11 "Character 2";
CM_ SG_ 2332524545 FW_revision_3_11 "Character 3";
CM_ SG_ 2332524545 FW_revision_4_11 "Character 3";
CM_ SG_ 2332524545 FW_revision_5_11 "Character 3";
CM_ SG_ 2332524545 FW_revision_6_11 "Character 3";
CM_ SG_ 2332524545 FW_revision_7_11 "Character 7";
CM_ SG_ 2332524545 FW_revision_8_11 "Character 8";
CM_ SG_ 2332524545 FW_revision_9_11 "Character 9";
CM_ SG_ 2332524545 FW_revision_10_11 "Character 10";
CM_ SG_ 2332524545 FW_revision_11_11 "Character 11";
CM_ SG_ 2332524545 FW_revision_12_11 "Character 12";
CM_ SG_ 2332524545 FW_revision_13_11 "Character 13";
CM_ SG_ 2332524545 FW_datecode_0_11 "Character 0";
CM_ SG_ 2332524545 FW_datecode_1_11 "Character 1";
CM_ SG_ 2332524545 FW_datecode_2_11 "Character 2";
CM_ SG_ 2332524545 FW_datecode_3_11 "Character 3";
CM_ SG_ 2332524545 FW_datecode_4_11 "Character 3";
CM_ SG_ 2332524545 FW_datecode_5_11 "Character 3";
CM_ SG_ 2332524545 FW_datecode_6_11 "Character 3";
CM_ SG_ 2332524545 FW_datecode_7_11 "Character 7";
CM_ SG_ 2332524545 FW_datecode_8_11 "Character 8";
CM_ SG_ 2332524545 FW_datecode_9_11 "Character 9";
CM_ SG_ 2332524545 FW_datecode_10_11 "Character 10";
CM_ SG_ 2332524545 FW_datecode_11_11 "Character 11";
CM_ SG_ 2332524545 FW_datecode_12_11 "Character 12";
CM_ SG_ 2332524545 FW_datecode_13_11 "Character 13";
CM_ SG_ 2332524557 FW_revision_0_11 "Character 0";
CM_ SG_ 2332524557 FW_revision_1_11 "Character 1";
CM_ SG_ 2332524557 FW_revision_2_11 "Character 2";
CM_ SG_ 2332524557 FW_revision_3_11 "Character 3";
CM_ SG_ 2332524557 FW_revision_4_11 "Character 3";
CM_ SG_ 2332524557 FW_revision_5_11 "Character 3";
CM_ SG_ 2332524557 FW_revision_6_11 "Character 3";
CM_ SG_ 2332524557 FW_revision_7_11 "Character 7";
CM_ SG_ 2332524557 FW_revision_8_11 "Character 8";
CM_ SG_ 2332524557 FW_revision_9_11 "Character 9";
CM_ SG_ 2332524557 FW_revision_10_11 "Character 10";
CM_ SG_ 2332524557 FW_revision_11_11 "Character 11";
CM_ SG_ 2332524557 FW_revision_12_11 "Character 12";
CM_ SG_ 2332524557 FW_revision_13_11 "Character 13";
CM_ SG_ 2332524557 FW_datecode_0_11 "Character 0";
CM_ SG_ 2332524557 FW_datecode_1_11 "Character 1";
CM_ SG_ 2332524557 FW_datecode_2_11 "Character 2";
CM_ SG_ 2332524557 FW_datecode_3_11 "Character 3";
CM_ SG_ 2332524557 FW_datecode_4_11 "Character 3";
CM_ SG_ 2332524557 FW_datecode_5_11 "Character 3";
CM_ SG_ 2332524557 FW_datecode_6_11 "Character 3";
CM_ SG_ 2332524557 FW_datecode_7_11 "Character 7";
CM_ SG_ 2332524557 FW_datecode_8_11 "Character 8";
CM_ SG_ 2332524557 FW_datecode_9_11 "Character 9";
CM_ SG_ 2332524557 FW_datecode_10_11 "Character 10";
CM_ SG_ 2332524557 FW_datecode_11_11 "Character 11";
CM_ SG_ 2332524557 FW_datecode_12_11 "Character 12";
CM_ SG_ 2332524557 FW_datecode_13_11 "Character 13";
CM_ SG_ 2332524546 Status_Error_Code_11 "Main status / error code as defined in errno/errno.h";
CM_ SG_ 2332524546 Data_1_11 "Additional information for the error/status";
CM_ SG_ 2332524546 Data_2_11 "Additional information for the error/status";
CM_ SG_ 2332524546 Data_3_11 "Additional information for the error/status";
CM_ SG_ 2332524551 Running_11 "Indicates if converter is running.";
CM_ SG_ 2332524551 PWM_11 "Indicates if converter is in PWM control mode.";
CM_ SG_ 2332524551 Current_dc_loop_mode_11 "Indicates if the current DC loop is enabled.";
CM_ SG_ 2332524551 Current_ac_loop_mode_11 "Indicates if the current AC loop is enabled.";
CM_ SG_ 2332524551 Buck_11 "Indicates if converter is in buck control mode.";
CM_ SG_ 2332524551 Boost_11 "Indicates if converter is in boost control mode.";
CM_ SG_ 2332524551 Precharge_dc_buck_mode_11 "Indicates if the precharge DC mode is enabled - buck direction.";
CM_ SG_ 2332524551 Precharge_dc_boost_mode_11 "Indicates if the precharge DC mode is enabled - boost direction.";
CM_ SG_ 2332524551 Rectifier_3ph_11 "Indicates if converter is in three-phase rectifier control mode.";
CM_ SG_ 2332524551 Stack_mode_11 "Indicates if converter is operating in stack mode.";
CM_ SG_ 2332524551 Master_11 "Indicates if converter is master in the stack.";
CM_ SG_ 2332524551 Slave_11 "Indicates if converter is slave in the stack.";
CM_ SG_ 2332524551 Inverter_1ph_11 "Indicates if converter is in single-phase inverter control mode.";
CM_ SG_ 2332524551 Boost_Neutral_11 "Indicates if converter is in boost control mode with neutral generation.";
CM_ SG_ 2332524551 Rectifier_1ph_11 "Indicates if converter is in single-phase rectifier control mode.";
CM_ SG_ 2332524551 Inverter_3ph_11 "Indicates if converter is in three-phase inverter control mode.";
CM_ SG_ 2332524551 Ready_11 "Indicates if converter is ready for operation.";
CM_ SG_ 2332524551 Inverter_1ph_Sync_11 "Single-phase inverter control mode with phase synchronization.";
CM_ SG_ 2332524551 Neutral_11 "Open-loop neutral generation.";
CM_ SG_ 2332524551 Rectifier_1ph_Buck_11 "Single-phase rectifier with buck on one leg.";
CM_ SG_ 2332524551 Inverter_1ph_Boost_11 "Single-phase inverter with boost on one leg.";
CM_ SG_ 2332524551 Rectifier_distributed_11 "Not available at the moment";
CM_ SG_ 2332524551 MPPT_buck_11 "Not available at the moment";
CM_ SG_ 2332524551 MPPT_boost_11 "Not available at the moment";
CM_ SG_ 2332524551 Buck_2p_float_11 "Buck in phases L1 and L2. Phase L3 is left floating (high impedance)";
CM_ SG_ 2332524551 Inverter_1ph_Distributed_11 "Single-phase inverter mode  distributed";
CM_ SG_ 2332524550 Protection_trip_internal_11 "This flagg is asserted if the interlock is open due to an internal fault condition (self-protection)";
CM_ SG_ 2332524550 Protection_trip_external_11 "This flag is asserted if the interlock is open due to an external condition received in the module.";
CM_ SG_ 2332524550 Phase_U_overcurrent_11 "Indicates an overcurrent event on Phase U. The overcurrent event is triggered when the measured phase current is over the programmed current limit.";
CM_ SG_ 2332524550 Phase_U_overvoltage_11 "Indicates an overvoltage event on Phase U. The overvoltage event is triggered when the measured phase voltage is over the programmed voltage limit.";
CM_ SG_ 2332524550 Phase_U_undervoltage_11 "Indicates an undervoltage event on Phase U. The overvoltage event is triggered when the measured phase voltage is over the programmed voltage limit.";
CM_ SG_ 2332524550 Phase_V_overvoltage_11 "Indicates an overvoltage event on Phase V. The overvoltage event is triggered when the measured phase voltage is over the programmed voltage limit.";
CM_ SG_ 2332524550 Phase_V_undervoltage_11 "Indicates an undervoltage event on Phase U. The overvoltage event is triggered when the measured phase voltage is over the programmed voltage limit.";
CM_ SG_ 2332524550 Phase_V_overcurrent_11 "Indicates an overcurrent event on Phase U. The overcurrent event is triggered when the measured phase current is over the programmed current limit.";
CM_ SG_ 2332524550 Phase_W_overvoltage_11 "Indicates an overvoltage event on Phase U. The overvoltage event is triggered when the measured phase voltage is over the programmed voltage limit.";
CM_ SG_ 2332524550 Phase_W_undervoltage_11 "Indicates an undervoltage event on Phase U. The overvoltage event is triggered when the measured phase voltage is over the programmed voltage limit.";
CM_ SG_ 2332524550 Phase_W_overcurrent_11 "Indicates an overcurrent event on Phase U. The overcurrent event is triggered when the measured phase current is over the programmed current limit.";
CM_ SG_ 2332524550 DC_undervoltage_11 "DC bus undervoltage condition. The undervoltage condition is asserted when the measured dc bus voltage is under the programmed voltage limit.";
CM_ SG_ 2332524550 DC_overvoltage_11 "DC bus overvoltage condition. The overvoltage condition is asserted when the measured dc bus voltage is over the programmed voltage limit.";
CM_ SG_ 2332524550 MOSFET_overtemperature_11 "This flag is asserted when the temperature of the MOSFET block is too high.";
CM_ SG_ 2332524550 Inductor_overtemperature_11 "This flag is asserted when the temperature of the inductor block is too high.";
CM_ SG_ 2332524550 Keep_Alive_not_served_11 "The Keep Alive feature is enabled but it was not served with the periodic message.";
CM_ SG_ 2332524550 PLL_not_locked_11 "Flag asserted when in rectifier modes, the PLL went out of lock condition";
CM_ SG_ 2332524550 Measurement_system_failure_11 "The voltages/currents measurement system is malfunctionning, and readouts are not guaranteed to be accurate.";
CM_ SG_ 2332524550 EEPROM_failure_11 "The configuration EEPROM failed to load or save the module configuration.";
CM_ SG_ 2332524547 Phase_U_11 "Phase current is the MOSFET loop current, in the branch U of the converter.";
CM_ SG_ 2332524547 Phase_V_11 "Phase current is the MOSFET loop current, in the branch V of the converter.";
CM_ SG_ 2332524547 Phase_W_11 "Phase current is the MOSFET loop current, in the branch W of the converter.";
CM_ SG_ 2332524560 Bus_current_11 "DC Bus current is possitive when current goes from input to output";
CM_ SG_ 2332524558 Phase_U_11 "Phase current is the MOSFET loop current, in the branch U of the converter.";
CM_ SG_ 2332524558 Phase_V_11 "Phase current is the MOSFET loop current, in the branch V of the converter.";
CM_ SG_ 2332524558 Phase_W_11 "Phase current is the MOSFET loop current, in the branch W of the converter.";
CM_ SG_ 2332524558 Stack_position_11 "Sender Stack position";
CM_ SG_ 2332524558 Group_ID_11 "Sender Group ID";
CM_ SG_ 2332524555 Phase_U_11 "RMS Phase current is the MOSFET loop current, in the branch U of the converter.";
CM_ SG_ 2332524555 Phase_V_11 "RMS Phase current is the MOSFET loop current, in the branch V of the converter.";
CM_ SG_ 2332524555 Phase_W_11 "RMS Phase current is the MOSFET loop current, in the branch W of the converter.";
CM_ SG_ 2332524556 Frequency_11 "Frequency of Three-Phase system";
CM_ SG_ 2332524556 Phase_11 "Phase of Three-Phase system";
CM_ SG_ 2332524549 Temp_Bridge_11 "Temperature of the MOSFET block";
CM_ SG_ 2332524549 Temp_Inductors_11 "Temperature of the inductors";
CM_ SG_ 2332524552 Phase_U_11 "The actual PWM duty cycle setpoint";
CM_ SG_ 2332524552 Phase_V_11 "The actual PWM duty cycle setpoint";
CM_ SG_ 2332524552 Phase_W_11 "The actual PWM duty cycle setpoint";
CM_ SG_ 2332524553 Current_setpoint_11 "The actual current setpoint";
CM_ SG_ 2332524553 Voltage_setpoint_11 "The actual voltage setpoint";
CM_ SG_ 2332524553 Frequency_setpoint_11 "The actual frequency setpoint";
CM_ SG_ 2332491872 Keep_Alive_Enable_11 "If set to 1, module will expect to receive this message every second repeatedly, or it will stop operation";
CM_ SG_ 2332491840 Converter_ON_11 "Enable the converter.";
CM_ SG_ 2332491840 PWM_ON_11 "Enable the PWM control mode.";
CM_ SG_ 2332491840 DC_Current_feedback_ON_11 "Enable the DC current loop";
CM_ SG_ 2332491840 AC_Current_feedback_ON_11 "Enable the AC current loop";
CM_ SG_ 2332491840 Buck_ON_11 "Enable the buck control mode.";
CM_ SG_ 2332491840 Boost_ON_11 "Enable the boost control mode.";
CM_ SG_ 2332491840 Rectifier_3ph_ON_11 "Enable the three-phase rectifier control mode.";
CM_ SG_ 2332491840 Inverter_1ph_ON_11 "Enable the single-phase inverter control mode.";
CM_ SG_ 2332491840 Rectifier_1ph_ON_11 "Enable the single-phase rectifier control mode.";
CM_ SG_ 2332491840 Boost_Neutral_ON_11 "Enable the boost control mode with neutral generation.";
CM_ SG_ 2332491840 Inverter_3ph_ON_11 "Enable the three-phase inverter control mode.";
CM_ SG_ 2332491840 Inverter_1ph_Sync_ON_11 "Single-phase inverter control mode with phase synchronization.";
CM_ SG_ 2332491840 Neutral_ON_11 "Open-loop neutral generation.";
CM_ SG_ 2332491840 Rectifier_1ph_Buck_ON_11 "Single-phase rectifier with buck on one leg.";
CM_ SG_ 2332491840 Inverter_1ph_Boost_ON_11 "Single-phase inverter with boost on one leg.";
CM_ SG_ 2332491840 Rectifier_Distributed_ON_11 "Single-phase (floating) distributed rectifier";
CM_ SG_ 2332491840 MPPT_buck_ON_11 "MPPT buck";
CM_ SG_ 2332491840 MPPT_boost_ON_11 "MPPT boost";
CM_ SG_ 2332491840 Buck_2p_float_ON_11 "Boost on L1 and L2. Floating L3 (high-impedance)";
CM_ SG_ 2332491840 Inverter_1ph_Distributed_ON_11 "Single-phase inverter mode distributed";
CM_ SG_ 2332491856 Clear_Interlock_11 "Clears the converter interlock";
CM_ SG_ 2332491856 Reset_Processor_11 "Reset the converter DSP";
CM_ SG_ 2332491856 Trip_Interlock_11 "Trip the inetrnal Interlock";
CM_ SG_ 2332491841 Reactive_current_setpoint_11 "This defines reactive current setpoint for 3-phase rectifier mode";
CM_ SG_ 2332491842 Phase_U_11 "The actual PWM duty cycle setpoint";
CM_ SG_ 2332491842 Phase_V_11 "The actual PWM duty cycle setpoint";
CM_ SG_ 2332491842 Phase_W_11 "The actual PWM duty cycle setpoint";
CM_ SG_ 2332491843 Current_setpoint_11 "Sets the output current setpoint. Active only when the current loop is enabled";
CM_ SG_ 2332491844 Voltage_setpoint_11 "Sets the output voltage setpoint. Active only when the voltage loop is enabled";
CM_ SG_ 2332491848 Frequency_setpoint_11 "Sets the frequency for single-phase and three-phase generator modes.";
CM_ SG_ 2332491849 Phase_setpoint_11 "Sets the phase for inverter control modes.";
CM_ SG_ 2332491845 Stack_position_11 "The converter position within the stack";
CM_ SG_ 2332491845 Stack_size_11 "How many PFC converters are in stack in total";
CM_ SG_ 2332491845 SN_number_11 "Unique module serial number";
CM_ SG_ 2332491824 Phase_voltage_min_11 "Minimum tolerated phase voltage";
CM_ SG_ 2332491824 Phase_voltage_max_11 "Maximum allowable phase voltage";
CM_ SG_ 2332491824 DC_voltage_min_11 "Minimum allowable dc voltage";
CM_ SG_ 2332491824 DC_voltage_max_11 "Maximum allowable dc voltage";
CM_ SG_ 2332491825 Phase_current_min_11 "Minimum allowable output current";
CM_ SG_ 2332491825 Phase_current_max_11 "Maximum allowable output current";
CM_ SG_ 2332491852 Group_ID_11 "Desired group ID for the device";
CM_ SG_ 2332524559 Group_ID_11 "Group ID of the device";
CM_ SG_ 2332491873 Factory_mode_11 "Customers MUST NOT USE this bit. If set to 1, module will enter in factory mode. ";
CM_ SG_ 2332491873 Silent_CAN_mode_11 "Customers MUST NOT USE this bit. If set to 1, module will enter in factory mode. ";
CM_ SG_ 2332491850 start_11 "Start automatic calibration. Multiplexer index must be 0!";
CM_ SG_ 2332491851 point_11 "Calibration point index.";
CM_ SG_ 2332491846 CRC_11 "Checksum of bytes 0 to 3, CRC-CCITT, corresponding to qChecksum (www.qt.io)";
CM_ SG_ 2332491847 CRC_11 "Checksum of bytes 0 to 3, CRC-CCITT, corresponding to qChecksum (www.qt.io)";
CM_ SG_ 2332524630 Current_U_High_11 "This flag is set if a hight current on U tripped the internal interlock";
CM_ SG_ 2332524630 Current_U_Low_11 "This flag is set if a low current on U tripped the internal interlock";
CM_ SG_ 2332524630 Current_V_High_11 "This flag is set if a hight current on V tripped the internal interlock";
CM_ SG_ 2332524630 Current_V_Low_11 "This flag is set if a low current on V tripped the internal interlock";
CM_ SG_ 2332524630 Current_W_High_11 "This flag is set if a hight current on W tripped the internal interlock";
CM_ SG_ 2332524630 Current_W_Low_11 "This flag is set if a low current on W tripped the internal interlock";
CM_ SG_ 2332524630 Voltage_DC_11 "This flag is set if a voltage on DC tripped the internal interlock";
CM_ SG_ 2332524630 Reboot_11 "This flag is set if a reboot tripped the internal interlock";
CM_ SG_ 2332524630 Unknown_11 "This flag the reason for the internal interlock is unknown";

BA_DEF_ BO_ "SystemMessageLongSymbol" STRING;

BA_ "SystemMessageLongSymbol" BO_ 2332491841 "AFE_Reactive_Current_Setpoint_Control_11";
BA_ "SystemMessageLongSymbol" BO_ 2332491848 "AFE_Frequency_Setpoint_Control_11";
BA_ "SystemMessageLongSymbol" BO_ 2332491888 "AFE_Rectifier_Setpoint_Control_11";
BA_ "SystemMessageLongSymbol" BO_ 2332491846 "_AFE_Calibration_Offset_Update_11";

VAL_ 2332524544 Device_type_11 7 "AFE";
VAL_ 2332524550 Protection_trip_internal_11 1 "fault";
VAL_ 2332524550 Protection_trip_external_11 1 "fault";
VAL_ 2332524550 Phase_U_overcurrent_11 1 "fault";
VAL_ 2332524550 Phase_U_overvoltage_11 1 "fault";
VAL_ 2332524550 Phase_U_undervoltage_11 1 "fault";
VAL_ 2332524550 Phase_V_overvoltage_11 1 "fault";
VAL_ 2332524550 Phase_V_undervoltage_11 1 "fault";
VAL_ 2332524550 Phase_V_overcurrent_11 1 "fault";
VAL_ 2332524550 Phase_W_overvoltage_11 1 "fault";
VAL_ 2332524550 Phase_W_undervoltage_11 1 "fault";
VAL_ 2332524550 Phase_W_overcurrent_11 1 "fault";
VAL_ 2332524550 DC_undervoltage_11 1 "fault";
VAL_ 2332524550 DC_overvoltage_11 1 "fault";
VAL_ 2332524550 MOSFET_overtemperature_11 1 "fault";
VAL_ 2332524550 Inductor_overtemperature_11 1 "fault";
VAL_ 2332524550 Keep_Alive_not_served_11 1 "fault";
VAL_ 2332524550 PLL_not_locked_11 1 "fault";
VAL_ 2332524550 NFO_11 1 "fault";
VAL_ 2332524550 Measurement_system_failure_11 1 "fault";
VAL_ 2332524550 EEPROM_failure_11 1 "fault";
VAL_ 2332524550 System_11 1 "fault";
VAL_ 2332524630 Current_U_High_11 1 "fault";
VAL_ 2332524630 Current_U_Low_11 1 "fault";
VAL_ 2332524630 Current_V_High_11 1 "fault";
VAL_ 2332524630 Current_V_Low_11 1 "fault";
VAL_ 2332524630 Current_W_High_11 1 "fault";
VAL_ 2332524630 Current_W_Low_11 1 "fault";
VAL_ 2332524630 Voltage_DC_11 1 "fault";
VAL_ 2332524630 Reboot_11 1 "fault";
VAL_ 2332524630 Unknown_11 1 "fault";
SIG_VALTYPE_ 2332524625 Current_U_11 : 1;
SIG_VALTYPE_ 2332524625 Current_V_11 : 1;
SIG_VALTYPE_ 2332524625 Current_W_11 : 1;
SIG_VALTYPE_ 2332524625 Voltage_U_11 : 1;
SIG_VALTYPE_ 2332524625 Voltage_V_11 : 1;
SIG_VALTYPE_ 2332524625 Voltage_W_11 : 1;
SIG_VALTYPE_ 2332524625 Voltage_DC_11 : 1;
SIG_VALTYPE_ 2332524626 Current_U_11 : 1;
SIG_VALTYPE_ 2332524626 Current_V_11 : 1;
SIG_VALTYPE_ 2332524626 Current_W_11 : 1;
SIG_VALTYPE_ 2332524626 Voltage_U_11 : 1;
SIG_VALTYPE_ 2332524626 Voltage_V_11 : 1;
SIG_VALTYPE_ 2332524626 Voltage_W_11 : 1;
SIG_VALTYPE_ 2332524626 Voltage_DC_11 : 1;
